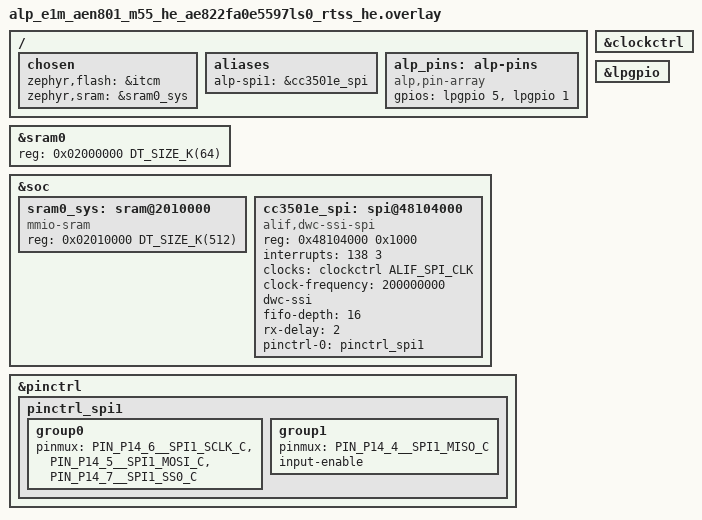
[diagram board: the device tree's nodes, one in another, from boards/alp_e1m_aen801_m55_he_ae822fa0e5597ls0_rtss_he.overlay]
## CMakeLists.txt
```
# SPDX-License-Identifier: Apache-2.0
#
# aen-cc3501e-wedge-postmortem -- reproduces the CC3501E WIFI_CONNECT_STA
# wedge on the E1M-AEN801 (Ensemble E8, M55-HE) and captures forensic
# evidence WHILE the link is still down, before any recovery is attempted.
# See src/main.c for the full phase-by-phase reasoning.
#
# Standalone Zephyr app (no alp_project.py board.yaml flow), same shape as
# its siblings aen-cc3501e-command-sweep / aen-cc3501e-socket-throughput:
# build with
#   ZEPHYR_BASE=<zephyr-base> west build \
#     -b alp_e1m_aen801_m55_he/ae822fa0e5597ls0/rtss_he <this-dir> -- \
#     "-DEXTRA_ZEPHYR_MODULES=<alp-sdk>;<hal_alif>"
# Zephyr applies boards/<fully-qualified-board>.overlay by itself.

cmake_minimum_required(VERSION 3.20)

find_package(Zephyr REQUIRED HINTS $ENV{ZEPHYR_BASE})
project(aen_cc3501e_wedge_postmortem LANGUAGES C)

target_sources(app PRIVATE src/main.c)
# The SoM bring-up TEMPLATE (see its own header comment): opens the
# inter-chip SPI1 bridge + WIFI_EN/nRESET, enables the LP-pad output
# drivers pinctrl does not reach, binds the READY line, and runs the
# power + reset sequence. Copied verbatim from aen-cc3501e-socket-throughput --
# byte-identical to the copies in every other aen-cc3501e-* sibling, same
# reasoning: a copyable template, not a cross-example reach-in.
target_sources(app PRIVATE src/cc3501e_bridge.c)
```

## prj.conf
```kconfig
# SPDX-License-Identifier: Apache-2.0
#
# Bench config for the CC3501E WIFI_CONNECT_STA wedge reproduction + forensic
# post-mortem on the E1M-AEN801 (Alif Ensemble E8, M55-HE). See src/main.c
# for what is captured, in what order, and why the order is load-bearing.

# --- Console -----------------------------------------------------------------
# Console: Alp UART console -- E1M edge UART0 (Alif UART5, P3_4/P3_5, 115200
# 8N1, NS16550), the E1M-AEN801 carrier console. The board _defconfig already
# selects it; set explicitly here so the app is self-describing.
CONFIG_SERIAL=y
CONFIG_CONSOLE=y
CONFIG_UART_CONSOLE=y
CONFIG_UART_INTERRUPT_DRIVEN=y
# Serial-less bench? Comment the four lines above and uncomment these to read
# 'ram_console_buf' over SWD instead -- the same toggle every sibling AEN
# bench app documents (see aen-rtc-tick-probe's prj.conf for the fuller note):
# CONFIG_RAM_CONSOLE=y
# CONFIG_RAM_CONSOLE_BUFFER_SIZE=4096
# CONFIG_UART_CONSOLE=n
CONFIG_PRINTK=y

# --- CC3501E bridge (SPI1 + WIFI_EN/nRESET/READY GPIOs) -----------------------
# The host-side chip driver (chips/cc3501e/*.c) plus the two peripheral
# classes it rides on: SPI for the inter-chip link (bus 1 -> the alp-spi1
# alias this app's overlay adds) and GPIO for WIFI_EN / nRESET / READY.
# Kconfig already enforces `depends on SPI && GPIO`; both are set explicitly
# here because this app has no board.yaml `peripherals:` block to generate
# them -- it is a standalone Zephyr app (see scripts/gen_example_alp_conf.py), same as its
# aen-cc3501e-* siblings. CONFIG_ALP_SDK_CHIP_CC3501E pulls in every
# chips/cc3501e/*.c TU (wifi/sockets/ble/gpio/spi/camera/power/ota/events),
# so this app can call cc3501e_wifi_connect()/cc3501e_hard_reset()/
# cc3501e_power_off() directly with no further Kconfig -- it never routes
# through the portable <alp/wifi.h> backend (CONFIG_ALP_SDK_WIFI_CC3501E),
# which attaches a DIFFERENT set of TUs this app has no use for.
CONFIG_SPI=y
CONFIG_GPIO=y
CONFIG_ALP_SDK=y
CONFIG_ALP_SDK_CHIP_CC3501E=y

# issue #2126: this app's whole purpose is to CAPTURE a live wedge for
# forensics (the rx_scratch peek, the READY GPIO read below), not clear it --
# the driver's own automatic recovery (cc3501e_link_check_and_recover(),
# wired into every worker-routed op's failure exit) would warm-reset the
# bridge the moment WIFI_CONNECT_STA's own timeout looks like the wedge this
# app is trying to catch, destroying the evidence before main() ever gets to
# read it.
CONFIG_ALP_SDK_CC3501E_AUTO_RECOVER=n

# CONFIG_ALP_SDK=y above defaults CONFIG_ALP_SDK_CONSOLE (zephyr/kconfigs/
# core.kconfig) to `y`, which `select`s CONFIG_SHELL -- pulling a `uart:~$`
# shell prompt into the middle of this app's own post-mortem transcript. This
# app never registers a shell command and never uses the `alp` console tree,
# so turn the console off explicitly rather than let its default drag the
# shell in unasked.
CONFIG_ALP_SDK_CONSOLE=n

# main()'s own cc3501e_t bridge handle (~32 KB, embeds several
# ALP_CC3501E_MAX_PAYLOAD scratch buffers) is STATIC in src/main.c, not
# automatic -- see that file's own header for why that discipline is
# load-bearing here, not optional: a sibling app in this tree died on its own
# prologue for exactly the mistake this app avoids by construction. 4096
# matches every other aen-cc3501e-* sibling that calls this driver with the
# same static discipline.
CONFIG_MAIN_STACK_SIZE=4096

# Logging ON, deliberately -- a desynced SPI link reports its decisive fault
# via LOG_ERR in the upstream DesignWare SPI driver, and this app is a bench
# diagnostic (its whole purpose is to capture a fault), not a shipping image.
# LOG_MODE_MINIMAL keeps it deferred-free.
CONFIG_LOG=y
CONFIG_LOG_MODE_MINIMAL=y

# --- Memory/cache: MATCH aen-cc3501e-command-sweep, not just its pin config --
# CONFIG_DCACHE=n for the SoC-wide reason every AEN801 bench app carries it
# (scripts/bench/aen/aen-bench-shared.conf's own header: "the E8 D-cache
# maintenance loop hangs on this silicon"), AND because this app's own
# post-mortem probes (the PING request-header transceive whose rx_scratch
# this app inspects, the READY GPIO read) ride the SAME SPI1 link every other
# AEN801 CC3501E bench app exercises -- that link's own overlay header
# documents a DW-SSI master that underruns its TX FIFO deasserting its own
# chip-select mid-frame as timing-sensitive to cache-on vs cache-off on this
# silicon. Running this app faster (cache-on, DTCM) than every other AEN801
# bench app that has ever driven this link would risk reproducing a
# DIFFERENT failure than the one this app exists to characterise. See the
# app overlay's own header for the matching zephyr,sram retarget this
# depends on.
CONFIG_DCACHE=n
```

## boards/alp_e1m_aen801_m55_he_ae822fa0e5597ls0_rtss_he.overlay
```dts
/*
 * Copyright (c) 2026 Alp Lab AB
 * SPDX-License-Identifier: Apache-2.0
 *
 * aen-cc3501e-wedge-postmortem -- app overlay for the E1M-AEN801 (Alif
 * Ensemble E8, M55-HE), bench RAM-run via J-Link.
 *
 * Everything below is transcribed from aen-evk-demo's phase-8 overlay block
 * (see that file's own header for the full derivation behind every value
 * here), reused byte-for-byte via aen-cc3501e-socket-throughput -- the
 * sibling app this one copies its bring-up template AND its memory
 * placement from (see src/cc3501e_bridge.h and that app's own overlay
 * header). Trimmed to exactly what the bridge needs: the SoM-internal Alif
 * <-> CC3501E link (SPI1 hardware SS0, the LP-GPIO island carrying
 * WIFI_EN/nRESET, and the READY input), the mandatory bench ITCM retarget,
 * AND (see the block below, deliberately kept even though no other phase's
 * hardware needs it here) the SRAM0 system-RAM placement -- this app's own
 * WEDGE_CONNECT wedge + post-mortem probes ride that exact SPI1 link, and a
 * faster-than-intended cache/DTCM path would shift the timing on precisely
 * the FIFO-refill axis the wedge itself lives on, making the reproduction
 * not comparable to any other AEN801 bench run. None of aen-evk-demo's
 * other thirteen phases' OWN hardware (PWM LED, SD, Ethernet, I2S/PDM,
 * JPEG) is declared here -- this app touches none of it, and carrying it
 * would only risk a pad conflict with the bridge pins.
 */
#include <zephyr/dt-bindings/pinctrl/alif-ensemble-pinctrl.h>
#include <zephyr/dt-bindings/gpio/gpio.h>

/*
 * ============================================================================
 * SYSTEM-RAM PLACEMENT -- MATCHES aen-evk-demo's phase 8, deliberately
 * ============================================================================
 *
 * This app trims aen-evk-demo's overlay down to exactly the SoM-internal
 * CC3501E bridge (see the block below) -- EXCEPT for this one piece, which
 * it keeps even though nothing else here needs it.
 *
 * aen-evk-demo's own overlay (see ITS header for the full derivation, which
 * this app does not repeat) documents that phase 8's SPI1 FIFO refill --
 * the SAME link this app's Part 2 clocks bulk STREAM_WRITE / SPI1_TRANSFER
 * frames over -- is the one phase sensitive to cache-on vs cache-off timing
 * on this silicon: a DesignWare SSI master that underruns its TX FIFO
 * deasserts its own chip-select mid-frame, and the demo runs from uncached
 * global SRAM0 with CONFIG_DCACHE=n (see prj.conf) rather than the M55's
 * tightly-coupled DTCM specifically to keep that FIFO-refill loop on the
 * same timing this silicon was bench-validated against.
 *
 * A throughput measurement over that link cannot run FASTER than the demo's
 * on precisely the axis the demo's own comment calls out -- that would not
 * be a number anyone else's AEN801 bench run could be compared against, it
 * would be measuring a different link. So this app carries the same
 * retarget, even though (unlike the demo) it has no Ethernet DMA rings or
 * JPEG buffers that need SRAM0 for their own reasons -- one disjoint 512 KiB
 * window is more than this app's own footprint needs, but a narrower
 * carve-out would only add a second constant to keep in sync with the demo
 * for no behavioural benefit.
 */
&sram0 {
	reg = <0x02000000 DT_SIZE_K(64)>;
};

&soc {
	/* Plain "mmio-sram", NOT "zephyr,memory-region" -- see aen-evk-demo's
	 * overlay for why a second memory-region-compatible node here would
	 * alias the linker region instead of extending it. */
	sram0_sys: sram@2010000 {
		compatible = "mmio-sram";
		reg = <0x02010000 DT_SIZE_K(512)>;
	};
};

/*
 * MANDATORY bench RAM-run retarget: run from ITCM so J-Link can loadbin+run
 * without programming MRAM, and drop the MCUboot code-partition fixup.
 * PATH-REFERENCE form (&itcm), NOT the <&itcm> phandle-array form -- the
 * phandle-array form yields CONFIG_FLASH_SIZE=0 and the image overflows the
 * (empty) FLASH region at link time. System RAM (zephyr,sram) is retargeted
 * separately, to &sram0_sys above -- see that block's header.
 */
/ {
	chosen {
		zephyr,flash = &itcm;
		/delete-property/ zephyr,code-partition;
		zephyr,sram = &sram0_sys;
	};
};

/*
 * ============================================================================
 * The SoM-internal Alif <-> CC3501E Wi-Fi/BLE bridge
 * ============================================================================
 *
 *     net          Alif pad       dir   CC3501E pad
 *     ----------   ------------   ---   ---------------------
 *     WIFI_EN      P15_5          out   (supply gate)
 *     E_WIFI.NRST  P15_1_FLEX     out   (reset)
 *     SPI1.SCK     P14_6          out   GPIO_27 (CC35 SPI0 slave)
 *     SPI1.MOSI    P14_5          out   GPIO_28
 *     SPI1.MISO    P14_4          in    GPIO_29
 *     SPI1.SS0     P14_7          out   CC35 SPI0 CSN
 *
 * READY (CC35 GPIO_17) is deliberately left off this table: on the R2
 * module this app targets it is NOT wired to Alif P2_6 -- P2_6 is E1M pad
 * AH7 / I2S1_SCLK (the EVK's Arduino CK_RST), a DIFFERENT net from GPIO_17
 * / E1M pad G3.  See the P2_6 comment further down and
 * chips/cc3501e/cc3501e_core.c's cc3501e_reply_gate() comment for the bench
 * evidence and how a board that genuinely wires it can opt in.
 *
 * SoM-INTERNAL fact (metadata/e1m_modules/aen/inter-chip.tsv), not an E1M
 * edge pad -- hence an app overlay, not the board tree.
 */
&pinctrl {
	/*
	 * SPI1 master on P14_6 (SCK) / P14_5 (MOSI) / P14_4 (MISO), plus the
	 * hardware SS0 chip-select on P14_7. SS0 is the dwc-ssi peripheral's
	 * OWN select -- not a GPIO bodge, not CS-less, not static-low: the
	 * master asserts and deasserts it per transfer, which is exactly what
	 * frames each phase of the bridge's request/reply exchange. Do NOT
	 * add cs-gpios here; that installs a software CS and breaks the
	 * framing the firmware side is built around.
	 *
	 * input-enable on MISO because on this SoC a pad's INPUT BUFFER is a
	 * PADCTRL bit that only pinctrl sets -- without it the pad never
	 * senses what the slave drives.
	 */
	pinctrl_spi1: pinctrl_spi1 {
		group0 {
			pinmux = <PIN_P14_6__SPI1_SCLK_C>, <PIN_P14_5__SPI1_MOSI_C>,
				 <PIN_P14_7__SPI1_SS0_C>;
		};
		group1 {
			pinmux = <PIN_P14_4__SPI1_MISO_C>;
			input-enable;
		};

	};
};

/* P2_6 (E1M AH7 / I2S1_SCLK) is NOT the CC3501E READY net on the R2 module this
 * bridge targets -- it is E1M pad AH7 / I2S1_SCLK, which the E1M EVK
 * carrier repurposes as the Arduino header's CK_RST (metadata/boards/
 * e1m-evk.yaml); the real READY net lands on E1M pad G3 / IO16 instead
 * (metadata/e1m_modules/aen/from-cc3501e.tsv). This app therefore does not
 * mux or input-enable P2_6, and does not wire fw->ready_pin -- see
 * src/cc3501e_bridge.c and chips/cc3501e/cc3501e_core.c's cc3501e_reply_gate()
 * comment. A board (or a hand-reworked r1 unit) that genuinely wires GPIO17
 * to P2_6 can opt back in: add a pinctrl group muxing PIN_P2_6__GPIO with
 * input-enable (applied inside pinctrl_spi1's single init pass, not a
 * standalone runtime one -- a second pinctrl pass after SPI1 is up killed
 * the bridge on silicon, aen-evk-demo bench-measured), enable &gpio2, add
 * an alp_pins entry for it, and set fw->ready_pin in
 * cc3501e_bridge_bringup().

/*
 * DWC_ssi SPI1 (AHB) -- the on-SoM CC3501E inter-chip link. Deliberately not
 * in ensemble_e8_peripherals.dtsi (which declares only the customer-facing
 * edge SPI0), so the consuming app declares it. reg 0x48104000 = the SPI1
 * base (+0x1000 per instance from spi0's 0x48103000).
 *
 * clock-frequency is REQUIRED, not decorative: without it spi_dw_alif's
 * configure takes the clock-control path, which fails -EINVAL for the
 * gateless dummy ALIF_SPI_CLK, and every transceive then returns
 * ALP_ERR_INVAL at zero SCLK. 200 MHz is the real SSI functional clock (E8
 * HWRM); BAUDR = clock-frequency / freq_hz, and cc3501e_bridge.h asks for
 * 25 MHz = /8.
 *
 * rx-delay: NOT what clocks the link -- src/cc3501e_bridge.c pokes
 * 0x48104000+0xf0 with CC3501E_BRIDGE_RX_SAMPLE_DLY right after
 * alp_spi_open() returns, and that constant (silicon-measured, see that
 * file's header) is what the bridge actually runs at. Kept at <2> anyway
 * because the poke is wrapped in `#if CC3501E_BRIDGE_RX_SAMPLE_DLY > 0` --
 * setting the constant to 0 does not mean "no delay", it means this
 * property is what survives.
 */
&clockctrl {
	status = "okay";
};

&soc {
	cc3501e_spi: spi@48104000 {
		compatible = "alif,dwc-ssi-spi";
		#address-cells = <1>;
		#size-cells = <0>;
		reg = <0x48104000 0x1000>;
		interrupts = <138 3>; /* BENCH-TBD: confirm SPI1 IRQ, same as aen-evk-demo */
		clocks = <&clockctrl ALIF_SPI_CLK>;
		clock-frequency = <200000000>;
		dwc-ssi;
		fifo-depth = <16>;
		rx-delay = <2>;
		pinctrl-0 = <&pinctrl_spi1>;
		pinctrl-names = "default";
		status = "okay";
	};
};

/*
 * The LP-GPIO island carries WIFI_EN (P15_5) and E_WIFI.NRST (P15_1_FLEX).
 * No pinctrl group is needed for their mux: P15_x function 0 -- the reset
 * default -- already IS LPGPIO. Turning the pads' OUTPUT DRIVERS on is a
 * separate matter and not a devicetree fact at all; see the raw PADCTRL
 * write in src/cc3501e_bridge.c and the comment above it.
 */
&lpgpio {
	status = "okay";
};

/ {
	aliases {
		/* bus_id 1 in alp_spi_open() -> this controller. */
		alp-spi1 = &cc3501e_spi;
	};

	/*
	 * Compact 2-entry control array for the SoM-internal CC3501E control
	 * nets, in the order cc3501e_bridge.h's CC3501E_BRIDGE_PIN_* indices
	 * expect. These are NOT E1M edge pads, so this app does not use the
	 * 52-slot positional E1M map; a production board file appends
	 * SoM-internal control nets after the E1M pad slots. No READY entry
	 * here -- see the P2_6 comment above &gpio2's removal further up.
	 *
	 * There must be exactly ONE "alp,pin-array" node in the tree -- a
	 * second one broke pin resolution outright on the aen-evk-demo bench
	 * (2026-08-26): the bridge failed as if WIFI_EN were absent, which
	 * reads like a hardware fault and is not one.
	 */
	alp_pins: alp-pins {
		compatible = "alp,pin-array";
		gpios = <&lpgpio 5 GPIO_ACTIVE_HIGH>, /* [0] WIFI_EN     (P15_5)      */
			<&lpgpio 1 GPIO_ACTIVE_HIGH>; /* [1] E_WIFI.NRST (P15_1_FLEX) */
	};
};
```

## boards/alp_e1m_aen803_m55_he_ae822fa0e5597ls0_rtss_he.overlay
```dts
/*
 * Copyright (c) 2026 Alp Lab AB
 * SPDX-License-Identifier: Apache-2.0
 *
 * aen-cc3501e-wedge-postmortem -- app overlay for the E1M-AEN803 (Alif
 * Ensemble E8, M55-HE), bench RAM-run via J-Link.
 *
 * Everything below is transcribed from aen-evk-demo's phase-8 overlay block
 * (see that file's own header for the full derivation behind every value
 * here), reused byte-for-byte via aen-cc3501e-socket-throughput -- the
 * sibling app this one copies its bring-up template AND its memory
 * placement from (see src/cc3501e_bridge.h and that app's own overlay
 * header). Trimmed to exactly what the bridge needs: the SoM-internal Alif
 * <-> CC3501E link (SPI1 hardware SS0, the LP-GPIO island carrying
 * WIFI_EN/nRESET, and the READY input), the mandatory bench ITCM retarget,
 * AND (see the block below, deliberately kept even though no other phase's
 * hardware needs it here) the SRAM0 system-RAM placement -- this app's own
 * WEDGE_CONNECT wedge + post-mortem probes ride that exact SPI1 link, and a
 * faster-than-intended cache/DTCM path would shift the timing on precisely
 * the FIFO-refill axis the wedge itself lives on, making the reproduction
 * not comparable to any other AEN803 bench run. None of aen-evk-demo's
 * other thirteen phases' OWN hardware (PWM LED, SD, Ethernet, I2S/PDM,
 * JPEG) is declared here -- this app touches none of it, and carrying it
 * would only risk a pad conflict with the bridge pins.
 */
#include <zephyr/dt-bindings/pinctrl/alif-ensemble-pinctrl.h>
#include <zephyr/dt-bindings/gpio/gpio.h>

/*
 * ============================================================================
 * SYSTEM-RAM PLACEMENT -- MATCHES aen-evk-demo's phase 8, deliberately
 * ============================================================================
 *
 * This app trims aen-evk-demo's overlay down to exactly the SoM-internal
 * CC3501E bridge (see the block below) -- EXCEPT for this one piece, which
 * it keeps even though nothing else here needs it.
 *
 * aen-evk-demo's own overlay (see ITS header for the full derivation, which
 * this app does not repeat) documents that phase 8's SPI1 FIFO refill --
 * the SAME link this app's Part 2 clocks bulk STREAM_WRITE / SPI1_TRANSFER
 * frames over -- is the one phase sensitive to cache-on vs cache-off timing
 * on this silicon: a DesignWare SSI master that underruns its TX FIFO
 * deasserts its own chip-select mid-frame, and the demo runs from uncached
 * global SRAM0 with CONFIG_DCACHE=n (see prj.conf) rather than the M55's
 * tightly-coupled DTCM specifically to keep that FIFO-refill loop on the
 * same timing this silicon was bench-validated against.
 *
 * A throughput measurement over that link cannot run FASTER than the demo's
 * on precisely the axis the demo's own comment calls out -- that would not
 * be a number anyone else's AEN803 bench run could be compared against, it
 * would be measuring a different link. So this app carries the same
 * retarget, even though (unlike the demo) it has no Ethernet DMA rings or
 * JPEG buffers that need SRAM0 for their own reasons -- one disjoint 512 KiB
 * window is more than this app's own footprint needs, but a narrower
 * carve-out would only add a second constant to keep in sync with the demo
 * for no behavioural benefit.
 */
&sram0 {
	reg = <0x02000000 DT_SIZE_K(64)>;
};

&soc {
	/* Plain "mmio-sram", NOT "zephyr,memory-region" -- see aen-evk-demo's
	 * overlay for why a second memory-region-compatible node here would
	 * alias the linker region instead of extending it. */
	sram0_sys: sram@2010000 {
		compatible = "mmio-sram";
		reg = <0x02010000 DT_SIZE_K(512)>;
	};
};

/*
 * MANDATORY bench RAM-run retarget: run from ITCM so J-Link can loadbin+run
 * without programming MRAM, and drop the MCUboot code-partition fixup.
 * PATH-REFERENCE form (&itcm), NOT the <&itcm> phandle-array form -- the
 * phandle-array form yields CONFIG_FLASH_SIZE=0 and the image overflows the
 * (empty) FLASH region at link time. System RAM (zephyr,sram) is retargeted
 * separately, to &sram0_sys above -- see that block's header.
 */
/ {
	chosen {
		zephyr,flash = &itcm;
		/delete-property/ zephyr,code-partition;
		zephyr,sram = &sram0_sys;
	};
};

/*
 * ============================================================================
 * The SoM-internal Alif <-> CC3501E Wi-Fi/BLE bridge
 * ============================================================================
 *
 *     net          Alif pad       dir   CC3501E pad
 *     ----------   ------------   ---   ---------------------
 *     WIFI_EN      P15_5          out   (supply gate)
 *     E_WIFI.NRST  P15_1_FLEX     out   (reset)
 *     SPI1.SCK     P14_6          out   GPIO_27 (CC35 SPI0 slave)
 *     SPI1.MOSI    P14_5          out   GPIO_28
 *     SPI1.MISO    P14_4          in    GPIO_29
 *     SPI1.SS0     P14_7          out   CC35 SPI0 CSN
 *
 * READY (CC35 GPIO_17) is deliberately left off this table: on the R2
 * module this app targets it is NOT wired to Alif P2_6 -- P2_6 is E1M pad
 * AH7 / I2S1_SCLK (the EVK's Arduino CK_RST), a DIFFERENT net from GPIO_17
 * / E1M pad G3.  See the P2_6 comment further down and
 * chips/cc3501e/cc3501e_core.c's cc3501e_reply_gate() comment for the bench
 * evidence and how a board that genuinely wires it can opt in.
 *
 * SoM-INTERNAL fact (metadata/e1m_modules/aen/inter-chip.tsv), not an E1M
 * edge pad -- hence an app overlay, not the board tree.
 */
&pinctrl {
	/*
	 * SPI1 master on P14_6 (SCK) / P14_5 (MOSI) / P14_4 (MISO), plus the
	 * hardware SS0 chip-select on P14_7. SS0 is the dwc-ssi peripheral's
	 * OWN select -- not a GPIO bodge, not CS-less, not static-low: the
	 * master asserts and deasserts it per transfer, which is exactly what
	 * frames each phase of the bridge's request/reply exchange. Do NOT
	 * add cs-gpios here; that installs a software CS and breaks the
	 * framing the firmware side is built around.
	 *
	 * input-enable on MISO because on this SoC a pad's INPUT BUFFER is a
	 * PADCTRL bit that only pinctrl sets -- without it the pad never
	 * senses what the slave drives.
	 */
	pinctrl_spi1: pinctrl_spi1 {
		group0 {
			pinmux = <PIN_P14_6__SPI1_SCLK_C>, <PIN_P14_5__SPI1_MOSI_C>,
				 <PIN_P14_7__SPI1_SS0_C>;
		};
		group1 {
			pinmux = <PIN_P14_4__SPI1_MISO_C>;
			input-enable;
		};

	};
};

/* P2_6 (E1M AH7 / I2S1_SCLK) is NOT the CC3501E READY net on the R2 module this
 * bridge targets -- it is E1M pad AH7 / I2S1_SCLK, which the E1M EVK
 * carrier repurposes as the Arduino header's CK_RST (metadata/boards/
 * e1m-evk.yaml); the real READY net lands on E1M pad G3 / IO16 instead
 * (metadata/e1m_modules/aen/from-cc3501e.tsv). This app therefore does not
 * mux or input-enable P2_6, and does not wire fw->ready_pin -- see
 * src/cc3501e_bridge.c and chips/cc3501e/cc3501e_core.c's cc3501e_reply_gate()
 * comment. A board (or a hand-reworked r1 unit) that genuinely wires GPIO17
 * to P2_6 can opt back in: add a pinctrl group muxing PIN_P2_6__GPIO with
 * input-enable (applied inside pinctrl_spi1's single init pass, not a
 * standalone runtime one -- a second pinctrl pass after SPI1 is up killed
 * the bridge on silicon, aen-evk-demo bench-measured), enable &gpio2, add
 * an alp_pins entry for it, and set fw->ready_pin in
 * cc3501e_bridge_bringup().

/*
 * DWC_ssi SPI1 (AHB) -- the on-SoM CC3501E inter-chip link. Deliberately not
 * in ensemble_e8_peripherals.dtsi (which declares only the customer-facing
 * edge SPI0), so the consuming app declares it. reg 0x48104000 = the SPI1
 * base (+0x1000 per instance from spi0's 0x48103000).
 *
 * clock-frequency is REQUIRED, not decorative: without it spi_dw_alif's
 * configure takes the clock-control path, which fails -EINVAL for the
 * gateless dummy ALIF_SPI_CLK, and every transceive then returns
 * ALP_ERR_INVAL at zero SCLK. 200 MHz is the real SSI functional clock (E8
 * HWRM); BAUDR = clock-frequency / freq_hz, and cc3501e_bridge.h asks for
 * 25 MHz = /8.
 *
 * rx-delay: NOT what clocks the link -- src/cc3501e_bridge.c pokes
 * 0x48104000+0xf0 with CC3501E_BRIDGE_RX_SAMPLE_DLY right after
 * alp_spi_open() returns, and that constant (silicon-measured, see that
 * file's header) is what the bridge actually runs at. Kept at <2> anyway
 * because the poke is wrapped in `#if CC3501E_BRIDGE_RX_SAMPLE_DLY > 0` --
 * setting the constant to 0 does not mean "no delay", it means this
 * property is what survives.
 */
&clockctrl {
	status = "okay";
};

&soc {
	cc3501e_spi: spi@48104000 {
		compatible = "alif,dwc-ssi-spi";
		#address-cells = <1>;
		#size-cells = <0>;
		reg = <0x48104000 0x1000>;
		interrupts = <138 3>; /* BENCH-TBD: confirm SPI1 IRQ, same as aen-evk-demo */
		clocks = <&clockctrl ALIF_SPI_CLK>;
		clock-frequency = <200000000>;
		dwc-ssi;
		fifo-depth = <16>;
		rx-delay = <2>;
		pinctrl-0 = <&pinctrl_spi1>;
		pinctrl-names = "default";
		status = "okay";
	};
};

/*
 * The LP-GPIO island carries WIFI_EN (P15_5) and E_WIFI.NRST (P15_1_FLEX).
 * No pinctrl group is needed for their mux: P15_x function 0 -- the reset
 * default -- already IS LPGPIO. Turning the pads' OUTPUT DRIVERS on is a
 * separate matter and not a devicetree fact at all; see the raw PADCTRL
 * write in src/cc3501e_bridge.c and the comment above it.
 */
&lpgpio {
	status = "okay";
};

/ {
	aliases {
		/* bus_id 1 in alp_spi_open() -> this controller. */
		alp-spi1 = &cc3501e_spi;
	};

	/*
	 * Compact 2-entry control array for the SoM-internal CC3501E control
	 * nets, in the order cc3501e_bridge.h's CC3501E_BRIDGE_PIN_* indices
	 * expect. These are NOT E1M edge pads, so this app does not use the
	 * 52-slot positional E1M map; a production board file appends
	 * SoM-internal control nets after the E1M pad slots. No READY entry
	 * here -- see the P2_6 comment above &gpio2's removal further up.
	 *
	 * There must be exactly ONE "alp,pin-array" node in the tree -- a
	 * second one broke pin resolution outright on the aen-evk-demo bench
	 * (2026-08-26): the bridge failed as if WIFI_EN were absent, which
	 * reads like a hardware fault and is not one.
	 */
	alp_pins: alp-pins {
		compatible = "alp,pin-array";
		gpios = <&lpgpio 5 GPIO_ACTIVE_HIGH>, /* [0] WIFI_EN     (P15_5)      */
			<&lpgpio 1 GPIO_ACTIVE_HIGH>; /* [1] E_WIFI.NRST (P15_1_FLEX) */
	};
};
```

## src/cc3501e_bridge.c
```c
/*
 * SPDX-License-Identifier: Apache-2.0
 * Copyright 2026 Alp Lab AB
 *
 * E1M-AEN SoM CC3501E bridge bring-up helper -- see cc3501e_bridge.h.
 */

#include "cc3501e_bridge.h"

#if defined(CONFIG_BOARD_ALP_E1M_AEN801_M55_HE)
#include <zephyr/arch/cpu.h>
#include <zephyr/sys/sys_io.h>
/*
 * AEN LP-pad mux (Alif Ensemble E8, M55-HE).  WIFI_EN (P15_5) and nRESET (P15_1)
 * are on the Alif LP-GPIO island, bound by the generic snps,designware-gpio driver
 * which does NOT apply Alif pinctrl -- so the LP pads stay un-muxed and their output
 * drivers OFF (confirmed on silicon: WIFI_EN never powers the CC3501E until these
 * regs are set).  0x23 = the Alif GPIO-output pad config (driver + read-enable +
 * drive strength).  TODO: drop this raw poke once the Alif GPIO backend muxes the LP
 * island via pinctrl.
 */
#define ALIF_LPGPIO_PADCTRL_BASE 0x42007000u
#define ALIF_PAD_GPIO_OUTPUT     0x23u
static void aen_lp_pads_enable_output(void)
{
	sys_write32(ALIF_PAD_GPIO_OUTPUT, ALIF_LPGPIO_PADCTRL_BASE + 5u * 4u); /* P15_5 WIFI_EN */
	sys_write32(ALIF_PAD_GPIO_OUTPUT, ALIF_LPGPIO_PADCTRL_BASE + 1u * 4u); /* P15_1 nRESET  */
}
#else
static inline void aen_lp_pads_enable_output(void)
{
}
#endif

alp_status_t cc3501e_bridge_bringup(cc3501e_t *fw)
{
	if (fw == NULL) {
		return ALP_ERR_INVAL;
	}

	/* 1. Control pins: WIFI_EN (supply gate) + nRESET.  These are Alif LP-GPIO
	 *    pads, not E1M edge pads -- the SoM owns them. */
	alp_gpio_t *wifi_en = alp_gpio_open(CC3501E_BRIDGE_PIN_WIFI_EN);
	alp_gpio_t *nrst    = alp_gpio_open(CC3501E_BRIDGE_PIN_NRST);
	if (wifi_en == NULL || nrst == NULL) {
		if (wifi_en != NULL) {
			alp_gpio_close(wifi_en);
		}
		if (nrst != NULL) {
			alp_gpio_close(nrst);
		}
		return ALP_ERR_NOT_PRESENT_ON_THIS_SOC;
	}
	aen_lp_pads_enable_output();
	(void)alp_gpio_configure(wifi_en, ALP_GPIO_OUTPUT, ALP_GPIO_PULL_NONE);
	(void)alp_gpio_configure(nrst, ALP_GPIO_OUTPUT, ALP_GPIO_PULL_NONE);

	/* 2. Inter-chip SPI (Alif = master).  CS is the dwc-ssi hardware SS0
	 *    muxed on P14_7; the app passes ALP_SPI_NO_CS so no software GPIO CS
	 *    is installed and the SPI controller drives SS0 per transfer.  Mode 0
	 *    matches the CC3501E vendor image frameFormat. */
	alp_spi_t *spi = alp_spi_open(&(alp_spi_config_t){
	    .bus_id        = CC3501E_BRIDGE_SPI_BUS_ID,
	    .freq_hz       = CC3501E_BRIDGE_SPI_FREQ_HZ,
	    .mode          = ALP_SPI_MODE_0,
	    .bits_per_word = 8u,
	    .cs_pin_id     = ALP_SPI_NO_CS,
	});
	if (spi == NULL) {
		alp_gpio_close(wifi_en);
		alp_gpio_close(nrst);
		return ALP_ERR_NOT_PRESENT_ON_THIS_SOC;
	}

#if CC3501E_BRIDGE_RX_SAMPLE_DLY > 0
	/* Raise the SCLK past 1 MHz: the DW SSI RX_SAMPLE_DLY register (0xf0) delays
	 * the MISO capture point by N ssi_clk cycles to cover the on-SoM trace + crossed
	 * data round-trip.  Zephyr spi_dw never writes it (leaves 0), so without this
	 * >1 MHz mis-samples MISO (cold reqhdr_rx=0xFFFFFFFF).  Written with SSI disabled
	 * (SSIENR=0); persists across the driver's per-transfer configure.  Value is
	 * silicon-tuned -- sweep CC3501E_BRIDGE_RX_SAMPLE_DLY at the target SCLK.
	 *
	 * SWEEP TRAP -- read before setting the constant to 0: the `#if > 0` above
	 * compiles this block out, so 0 does not mean "no delay", it means the SPI
	 * node's `rx-delay` devicetree value is left in place.  aen-cc3501e-bringup
	 * and aen-evk-demo declare rx-delay = <2>, so a naive N=0 sweep point on
	 * those two silently measures 2.  Read 0x481040F0 back to see what the link
	 * is actually running at. */
	{
		volatile uint32_t *ssienr =
		    (volatile uint32_t *)(uintptr_t)(CC3501E_BRIDGE_SPI1_BASE + 0x08u);
		volatile uint32_t *rsd = (volatile uint32_t *)(uintptr_t)(CC3501E_BRIDGE_SPI1_BASE + 0xf0u);
		uint32_t           en  = *ssienr;
		*ssienr                = 0u;
		*rsd                   = (uint32_t)CC3501E_BRIDGE_RX_SAMPLE_DLY;
		*ssienr                = en;
	}
#endif

	/* 3. Bind the bus + control pins; attach the GPIO proxy (proxied E1M IOs then
	 *    route over the bridge); run the power + reset sequence (TI SWRU626 + the
	 *    Puya cold-boot hard-reset workaround).  Leaves WIFI_EN HIGH. */
	(void)cc3501e_init(fw, spi);
	fw->enable_pin = wifi_en;
	fw->reset_pin  = nrst;
	/* Optional host-IRQ/READY line (r2 SS0+IRQ bridge): CC35 GPIO17 -> Alif P2_6.
	 * Open + configure as input; if the board doesn't wire it (alp_pins[2] absent),
	 * alp_gpio_open returns NULL and the driver keeps the fixed-gap fallback. */
	alp_gpio_t *ready = alp_gpio_open(CC3501E_BRIDGE_PIN_READY);
	if (ready != NULL) {
		(void)alp_gpio_configure(ready, ALP_GPIO_INPUT, ALP_GPIO_PULL_NONE);
		fw->ready_pin = ready;
	}
#ifdef CONFIG_ALP_SDK_GPIO_CC3501E_PROXY
	(void)alp_gpio_cc3501e_attach(fw);
#endif
#ifdef CONFIG_ALP_SDK_WIFI_CC3501E
	(void)alp_wifi_cc3501e_attach(fw);
#endif
#ifdef CONFIG_ALP_SDK_BLE_CC3501E
	(void)alp_ble_cc3501e_attach(fw);
#endif
	return cc3501e_reset(fw);
}
```

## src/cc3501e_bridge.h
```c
/*
 * SPDX-License-Identifier: Apache-2.0
 * Copyright 2026 Alp Lab AB
 *
 * One-call bring-up of the E1M-AEN SoM's CC3501E Wi-Fi 6 / BLE coprocessor over the
 * inter-chip SPI bridge -- the SoM bring-up TEMPLATE for applications.
 *
 * The CC3501E is part of the SoM (module U4 = BDE-BW35N): the application does NOT
 * touch the raw SPI bus or the WIFI_EN / nRESET control pins.  It calls
 * cc3501e_bridge_bringup() once, gets a ready @ref cc3501e_t, and from there uses the
 * portable surfaces:
 *   - cc3501e_* (chips/cc3501e)            -- MAC / Wi-Fi / BLE / GPIO-proxy / OTA
 *   - alp_gpio_open(ALP_E1M_GPIO_IOxx)         -- proxied E1M IOs (when the proxy is built)
 *
 * To reuse in your own AEN application: copy this pair (cc3501e_bridge.{c,h}) into your
 * app, or call cc3501e_bridge_bringup() directly.  The bus / pins / clock are the
 * E1M-AEN SoM defaults below; a board variant overrides only those macros -- the SoM
 * stays swappable without touching application code.
 */

#ifndef CC3501E_BRIDGE_H
#define CC3501E_BRIDGE_H

#include <alp/peripheral.h>    /* alp_status_t */
#include <alp/chips/cc3501e.h> /* cc3501e_t */

/* ---- E1M-AEN SoM bridge defaults (override per board variant) ---------------- */

/* Inter-chip SPI: Alif = master, CC3501E = slave.  P14_7 is muxed as the
 * dwc-ssi hardware SS0 chip-select; ALP_SPI_NO_CS means "no software GPIO CS"
 * here, so the controller frames each protocol phase.  Mode 0 matches the
 * CC3501E vendor image frameFormat. */
#ifndef CC3501E_BRIDGE_SPI_BUS_ID
#define CC3501E_BRIDGE_SPI_BUS_ID 1u
#endif
#ifndef CC3501E_BRIDGE_SPI_FREQ_HZ
/* 25 MHz = 200 MHz SSI functional clock / 8.
 *
 * The CC3501E peripheral-mode maximum is 30 MHz, NOT the 15 MHz this comment
 * claimed for most of the bring-up: datasheet SWRS343A section 6.14.2.3.3,
 * `fsclk SPI clock frequency, Peripheral Mode, MAX 30 MHz` (Controller Mode is
 * 40 MHz).  Every earlier ceiling argument here was built on the wrong number.
 *
 * 25 MHz is the fastest LEGAL step available: the DW SSI BAUDR divisor must be
 * EVEN, so from 200 MHz the neighbours are /8 = 25 MHz and /6 = 33.3 MHz, and
 * 33.3 is 11% over the part's maximum.  Reaching exactly 30 MHz would require
 * retargeting the SSI functional clock itself (AE822 HWRM section 8.3.5) --
 * ALIF_SPI_CLK is a frequency-only dummy in the dtsi with no divider control,
 * so there is no software knob for it here.
 *
 * REQUIRES an RX sample delay: at a 40 ns bit period the MISO capture does not
 * land on its own.  That delay comes from CC3501E_BRIDGE_RX_SAMPLE_DLY below --
 * NOT from the SPI node's `rx-delay` property, which the poke in
 * cc3501e_bridge.c overwrites.  The measured working span is in that constant's
 * comment.
 *
 * It does not raise throughput -- silicon-measured
 * 2026-08-24: 682 kB/s at 25 MHz vs 678 kB/s at 14.29 MHz on PIO, 704 vs 701 on
 * DMA, because wire time is only ~554 us of a ~2459 us transaction and the rest
 * is per-frame protocol cost on both ends.  It is worth taking anyway: each
 * transfer occupies the bus for ~44% less time, which is CPU and bus budget
 * handed back to everything else on the SoM.
 *
 * The 14.29 MHz predecessor was scope-confirmed at 14.20-14.26 MHz, which is
 * what validates the 200 MHz functional-clock figure the divider assumes.  A
 * board with longer traces should re-check MISO capture before adopting 25 MHz.
 *
 * SEPARATE, PRE-EXISTING DEFECT (do not blame this clock for it): a bulk read
 * intermittently desyncs partway through -- roughly 1 run in 2-3, at anywhere
 * from 61 kB to 212 kB in -- and then never recovers for the caller's whole
 * retry budget.  It reproduces at 14.29 MHz TOO, so it is not a clock artifact.
 * Signature (host-side, request-header phase of CMD_SOCK_RECV 0x23): the
 * slave's in-band idle marker reads [02 00 00 00] once and then [00 00 00 00]
 * forever instead of A5 A5 A5 A5 -- i.e. the slave is stuck mid-reply on a
 * transfer it armed earlier and never completed.  With
 * SPI_TRANSFER_RETURN_PARTIAL deliberately off, a CS deassert does not complete
 * it, and NEITHER slave self-heal fires (g_resync_count does not move -- the
 * slave is not misframing; g_arm_fail_count does not move -- the arm succeeded).
 * Clocking a full idle frame from the host to satisfy the outstanding count was
 * tried and did NOT recover it.  The fix likely belongs on the slave: a
 * stall watchdog that calls bridge_transport_spi_hw_reinit() when an armed
 * transfer has not completed for N ms. */
#define CC3501E_BRIDGE_SPI_FREQ_HZ 25000000u
#endif

/* CC3501E control pins on the Alif LP-GPIO island (NOT E1M edge pads):
 * WIFI_EN = supply gate (P15_5), nRESET = reset (P15_1_FLEX). */
#ifndef CC3501E_BRIDGE_PIN_WIFI_EN
#define CC3501E_BRIDGE_PIN_WIFI_EN 0u
#endif
#ifndef CC3501E_BRIDGE_PIN_NRST
#define CC3501E_BRIDGE_PIN_NRST 1u
#endif
/* OPTIONAL host-IRQ/READY input.  ready_pin has no fixed index or macro
 * here on purpose: on a board where the CC3501E's GPIO17 READY net is
 * actually routed to the host, set fw->ready_pin (in
 * cc3501e_bridge_bringup() below) to whatever Alif pin that board wires it
 * to.  When set, cc3501e_reply_gate() (chips/cc3501e/cc3501e_core.c) can
 * only ever ADD delay to a reply phase, never remove it, so opting in on a
 * board where the wiring is wrong costs at most CC3501E_READY_WAIT_US
 * before the driver's own (recoverable) stuck-LOW latch gives up on it --
 * it is always safe to try FOR LINK TIMING.  It is not free, though: this
 * wait runs while cc3501e_request() holds its internal transport lock, so
 * a wrong or slow ready_pin can make another caller on the same ctx see
 * ALP_ERR_BUSY after CONFIG_ALP_SDK_CC3501E_REQUEST_LOCK_TIMEOUT_MS -- see
 * <alp/chips/cc3501e/core.h>'s ready_pin doc.
 *
 * NOT Alif P2_6 on e1m-aen-evk-01's R2 module: P2_6 there is E1M pad AH7 /
 * I2S1_SCLK (the EVK's Arduino CK_RST, metadata/boards/e1m-evk.yaml), and
 * the CC3501E GPIO17 READY net lands on E1M pad G3 / IO16 instead
 * (metadata/e1m_modules/aen/from-cc3501e.tsv).  cc3501e_bridge_bringup()
 * below leaves ready_pin NULL by default on that module -- see
 * cc3501e_reply_gate()'s own doc comment for the bench evidence. */

/* DW SSI SPI1 base (0x48104000) + RX_SAMPLE_DLY to run the bridge SCLK above
 * 1 MHz.  spi_dw_configure never writes RX_SAMPLE_DLY (0xf0), so without the
 * poke in cc3501e_bridge.c the master samples MISO at the SCLK edge, before the
 * on-SoM trace + crossed-data round-trip returns the CC35's bit, and anything
 * above 1 MHz mis-samples.  Setting it delays the capture by N ssi_clk
 * (200 MHz) cycles -- 5 ns per step.
 *
 * 4 is silicon-measured at the 25 MHz working point (40 ns bit period) on
 * E1M-AEN803 serial 2026W36-0002.  N was swept 0..10 with 0x481040F0 read back
 * each time to confirm the value took, using aen-evk-demo phase 8 as the
 * workload:
 *
 *   N = 0..7   PASS, 2-3 runs each: bring-up 0, PING on attempt 1 of 25,
 *              byte-exact MAC, scan 0, BLE 0.
 *   N = 8      FAIL, 3 runs of 3: bring-up still returns 0, but the link never
 *              answers -- PING -> -5 after all 25 attempts.
 *   N = 9      PASS, 2 runs of 2.
 *   N = 10     PASS, 3 runs of 3, but one run returned a MAC with a single bit
 *              flipped in byte 0.
 *
 * 4 is the centre of the measured-good 0..7 span: +4 steps (20 ns, half a bit
 * period) below the failure, and the low side is not a cliff at all since 0
 * itself is clean.  Do NOT read 8/9/10 as a monotone upper boundary -- 8
 * hard-fails while 9 and 10 pass, which this sweep did not explain.  Treat
 * everything above 7 as unqualified, not as graded margin.
 *
 * The "4..8 all clean cold+warm" window this comment used to claim was taken on
 * e1m-aen-evk-01 at ~14.3 MHz -- a different board at roughly half the clock,
 * so it is not comparable and is not evidence for 25 MHz on this one.
 *
 * 0 does NOT mean "no delay": it compiles the poke out, leaving whatever the
 * SPI node's `rx-delay` property put there (see cc3501e_bridge.c).  Re-sweep if
 * the SoM trace lengths or the SCLK change. */
#ifndef CC3501E_BRIDGE_SPI1_BASE
#define CC3501E_BRIDGE_SPI1_BASE 0x48104000u
#endif
#ifndef CC3501E_BRIDGE_RX_SAMPLE_DLY
#define CC3501E_BRIDGE_RX_SAMPLE_DLY 4u
#endif

/**
 * @brief Bring up the SoM's CC3501E coprocessor over the inter-chip bridge.
 *
 * Opens the hardware-SS0 bridge SPI + the WIFI_EN / nRESET control pins, binds
 * them to @p fw, attaches the GPIO proxy (when CONFIG_ALP_SDK_GPIO_CC3501E_PROXY is
 * built), and runs the power + reset sequence (TI SWRU626 + the Puya cold-boot
 * hard-reset workaround).  Blocks ~900 ms for the boot budget; leaves WIFI_EN HIGH.
 *
 * @param fw  Caller-owned handle, populated on success.  Use it with cc3501e_*.
 * @return ALP_OK with @p fw ready; ALP_ERR_NOT_PRESENT_ON_THIS_SOC if the SPI bus /
 *         control pins are absent (check the board overlay); otherwise the reset
 *         sequence status.  On any failure @p fw is left un-bound (do not use it).
 */
alp_status_t cc3501e_bridge_bringup(cc3501e_t *fw);

#endif /* CC3501E_BRIDGE_H */
```
